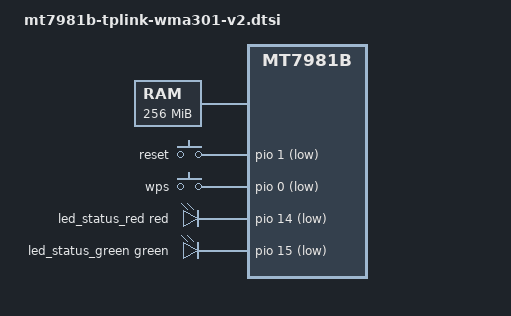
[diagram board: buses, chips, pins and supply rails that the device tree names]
// SPDX-License-Identifier: GPL-2.0-or-later OR MIT

/dts-v1/;
#include "mt7981b-tplink-wma301-common.dtsi"

/ {
	aliases {
		serial0 = &uart0;
		led-boot = &led_status_red;
		led-failsafe = &led_status_red;
		led-running = &led_status_green;
		led-upgrade = &led_status_green;
	};

	chosen: chosen {
		stdout-path = "serial0:115200n8";
	};

	memory {
		reg = <0 0x40000000 0 0x10000000>;
	};

	gpio-keys {
		compatible = "gpio-keys";

		reset {
			label = "reset";
			linux,code = <KEY_RESTART>;
			gpios = <&pio 1 GPIO_ACTIVE_LOW>;
		};

		wps {
			label = "wps";
			linux,code = <KEY_WPS_BUTTON>;
			gpios = <&pio 0 GPIO_ACTIVE_LOW>;
		};
	};

	leds {
		compatible = "gpio-leds";

		led_status_red: red {
			function = LED_FUNCTION_STATUS;
			color = <LED_COLOR_ID_RED>;
			gpios = <&pio 14 GPIO_ACTIVE_LOW>;
		};

		led_status_green: green {
			function = LED_FUNCTION_STATUS;
			color = <LED_COLOR_ID_GREEN>;
			gpios = <&pio 15 GPIO_ACTIVE_LOW>;
		};
	};
};
